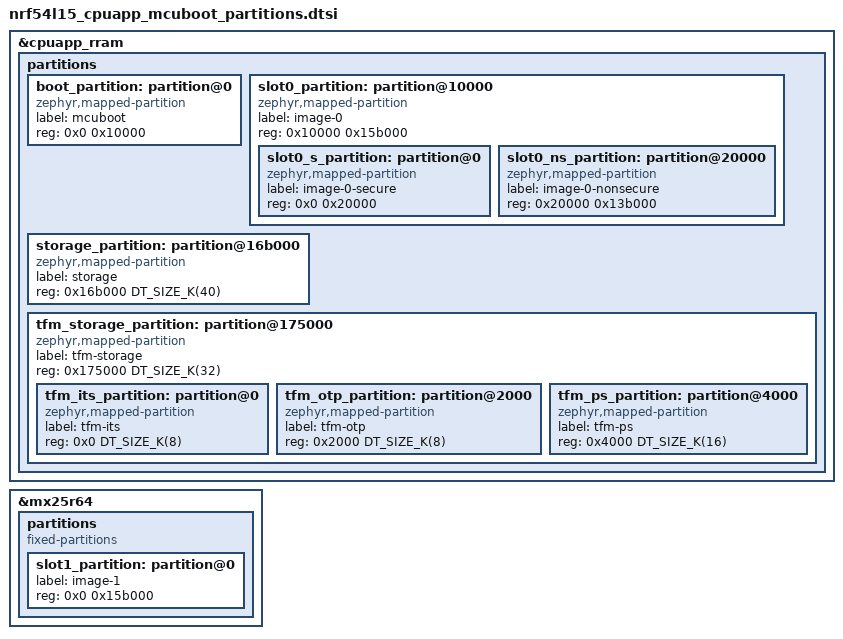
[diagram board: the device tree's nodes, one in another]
/*
 * Copyright (c) 2026 Nordic Semiconductor ASA
 *
 * SPDX-License-Identifier: LicenseRef-Nordic-5-Clause
 *
 * MCUboot + TF-M RRAM layout for nRF54L15 DK (partition nodes only).
 * Include after deleting the board default partition nodes.
 */

&cpuapp_rram {
	partitions {
		ranges;
		#address-cells = <1>;
		#size-cells = <1>;

		boot_partition: partition@0 {
			compatible = "zephyr,mapped-partition";
			label = "mcuboot";
			reg = <0x0 0x10000>;
		};

		slot0_partition: partition@10000 {
			compatible = "zephyr,mapped-partition";
			label = "image-0";
			reg = <0x10000 0x15b000>;
			ranges = <0x0 0x10000 0x15b000>;
			#address-cells = <1>;
			#size-cells = <1>;

			slot0_s_partition: partition@0 {
				compatible = "zephyr,mapped-partition";
				label = "image-0-secure";
				reg = <0x0 0x20000>;
			};

			slot0_ns_partition: partition@20000 {
				compatible = "zephyr,mapped-partition";
				label = "image-0-nonsecure";
				reg = <0x20000 0x13b000>;
			};
		};

		storage_partition: partition@16b000 {
			compatible = "zephyr,mapped-partition";
			label = "storage";
			reg = <0x16b000 DT_SIZE_K(40)>;
		};

		tfm_storage_partition: partition@175000 {
			compatible = "zephyr,mapped-partition";
			label = "tfm-storage";
			reg = <0x175000 DT_SIZE_K(32)>;
			ranges = <0x0 0x175000 DT_SIZE_K(32)>;
			#address-cells = <1>;
			#size-cells = <1>;

			tfm_its_partition: partition@0 {
				compatible = "zephyr,mapped-partition";
				label = "tfm-its";
				reg = <0x0 DT_SIZE_K(8)>;
			};

			tfm_otp_partition: partition@2000 {
				compatible = "zephyr,mapped-partition";
				label = "tfm-otp";
				reg = <0x2000 DT_SIZE_K(8)>;
			};

			tfm_ps_partition: partition@4000 {
				compatible = "zephyr,mapped-partition";
				label = "tfm-ps";
				reg = <0x4000 DT_SIZE_K(16)>;
			};
		};
	};
};

&mx25r64 {
	status = "okay";

	partitions {
		compatible = "fixed-partitions";
		#address-cells = <1>;
		#size-cells = <1>;

		slot1_partition: partition@0 {
			label = "image-1";
			reg = <0x0 0x15b000>;
		};
	};
};
